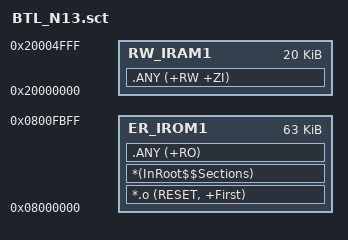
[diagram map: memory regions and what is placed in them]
; Linker memory map for STM32F103C8T6 (64 KiB Flash / 20 KiB RAM).
; Last 1 KiB Flash page 0x0800FC00..0x0800FFFF reserved for settings.
LR_IROM1 0x08000000 0x0000FC00  {
    ER_IROM1 0x08000000 0x0000FC00  {
        *.o (RESET, +First)
        *(InRoot$$Sections)
        .ANY (+RO)
    }
    RW_IRAM1 0x20000000 0x00005000  {
        .ANY (+RW +ZI)
    }
}
